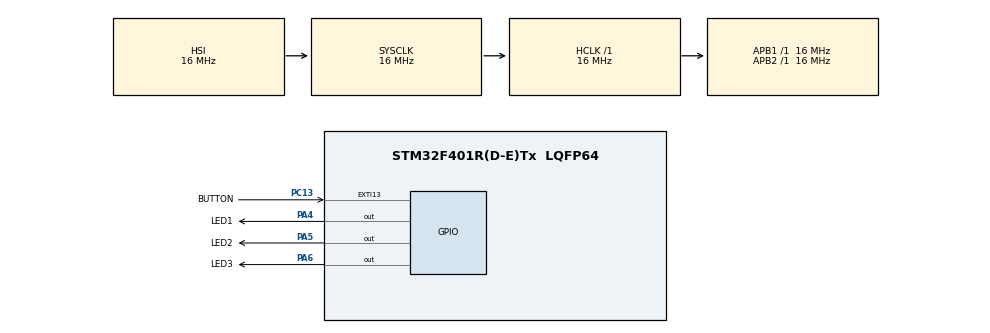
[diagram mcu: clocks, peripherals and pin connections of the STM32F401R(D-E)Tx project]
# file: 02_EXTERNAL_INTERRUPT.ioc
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Mcu.Family=STM32F4
Mcu.Name=STM32F401R(D-E)Tx
Mcu.Package=LQFP64
NVIC.EXTI15_10_IRQn=true\:0\:0\:false\:false\:true\:true\:true\:true
NVIC.PriorityGroup=NVIC_PRIORITYGROUP_4
PA13.Mode=Serial_Wire
PA13.Signal=SYS_JTMS-SWDIO
PA14.Mode=Serial_Wire
PA14.Signal=SYS_JTCK-SWCLK
PA4.GPIO_Label=LED1
PA4.Signal=GPIO_Output
PA5.GPIO_Label=LED2
PA5.Signal=GPIO_Output
PA6.GPIO_Label=LED3
PA6.Signal=GPIO_Output
PC13-ANTI_TAMP.GPIO_Label=BUTTON
PC13-ANTI_TAMP.GPIO_ModeDefaultEXTI=GPIO_MODE_IT_FALLING
PC13-ANTI_TAMP.GPIO_PuPd=GPIO_PULLUP
PC13-ANTI_TAMP.Signal=GPXTI13
ProjectManager.HeapSize=0x200
ProjectManager.StackSize=0x400
ProjectManager.TargetToolchain=STM32CubeIDE
RCC.AHBFreq_Value=16000000
RCC.APB1Freq_Value=16000000
RCC.APB2Freq_Value=16000000
RCC.CortexFreq_Value=16000000
RCC.HSE_VALUE=25000000
RCC.HSI_VALUE=16000000
RCC.LSE_VALUE=32768
RCC.SYSCLKFreq_VALUE=16000000
RCC.VCOOutputFreq_Value=192000000
board=custom

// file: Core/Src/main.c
/* USER CODE BEGIN Header */
/**
  ******************************************************************************
  * @file           : main.c
  * @brief          : Main program body
  ******************************************************************************
  * @attention
  *
  * Copyright (c) 2023 STMicroelectronics.
  * All rights reserved.
  *
  * This software is licensed under terms that can be found in the LICENSE file
  * in the root directory of this software component.
  * If no LICENSE file comes with this software, it is provided AS-IS.
  *
  ******************************************************************************
  */
/* USER CODE END Header */
#include "main.h"

/* USER CODE BEGIN Includes */
#include <stdbool.h>
/* USER CODE END Includes */

/* USER CODE BEGIN PV */
__IO uint8_t contador = 0; //__IO es una variable de tipo volatile
__IO bool flag = false;
/* USER CODE END PV */

void SystemClock_Config(void);
static void MX_GPIO_Init(void);

int main(void)
{

  /* MCU Configuration--------------------------------------------------------*/

  /* Reset of all peripherals, Initializes the Flash interface and the Systick. */
  HAL_Init();

  /* Configure the system clock */
  SystemClock_Config();

  /* Initialize all configured peripherals */
  MX_GPIO_Init();

  /* Infinite loop */
  while (1)
  {
	  if(flag){
		  contador++;
		  flag =  false;
		  if(contador>8){
			  contador = 0;
		  }

	  }

	  if(contador==2){
		  HAL_GPIO_WritePin(LED1_GPIO_Port, LED1_Pin, SET);
	  }else{
		  HAL_GPIO_WritePin(LED1_GPIO_Port, LED1_Pin, RESET);
	  }

	  if(contador==5){
		  HAL_GPIO_WritePin(LED2_GPIO_Port, LED2_Pin, SET);
	  }else{
		  HAL_GPIO_WritePin(LED2_GPIO_Port, LED2_Pin, RESET);
	  }

	  if(contador==7){
		  HAL_GPIO_WritePin(LED3_GPIO_Port, LED3_Pin, SET);
	  }else{
		  HAL_GPIO_WritePin(LED3_GPIO_Port, LED3_Pin, RESET);
	  }

  }
}

void SystemClock_Config(void)
{
  RCC_OscInitTypeDef RCC_OscInitStruct = {0};
  RCC_ClkInitTypeDef RCC_ClkInitStruct = {0};

  /** Configure the main internal regulator output voltage
  */
  __HAL_RCC_PWR_CLK_ENABLE();
  __HAL_PWR_VOLTAGESCALING_CONFIG(PWR_REGULATOR_VOLTAGE_SCALE2);

  /** Initializes the RCC Oscillators according to the specified parameters
  * in the RCC_OscInitTypeDef structure.
  */
  RCC_OscInitStruct.OscillatorType = RCC_OSCILLATORTYPE_HSI;
  RCC_OscInitStruct.HSIState = RCC_HSI_ON;
  RCC_OscInitStruct.HSICalibrationValue = RCC_HSICALIBRATION_DEFAULT;
  RCC_OscInitStruct.PLL.PLLState = RCC_PLL_NONE;
  if (HAL_RCC_OscConfig(&RCC_OscInitStruct) != HAL_OK)
  {
    Error_Handler();
  }

  /** Initializes the CPU, AHB and APB buses clocks
  */
  RCC_ClkInitStruct.ClockType = RCC_CLOCKTYPE_HCLK|RCC_CLOCKTYPE_SYSCLK
                              |RCC_CLOCKTYPE_PCLK1|RCC_CLOCKTYPE_PCLK2;
  RCC_ClkInitStruct.SYSCLKSource = RCC_SYSCLKSOURCE_HSI;
  RCC_ClkInitStruct.AHBCLKDivider = RCC_SYSCLK_DIV1;
  RCC_ClkInitStruct.APB1CLKDivider = RCC_HCLK_DIV1;
  RCC_ClkInitStruct.APB2CLKDivider = RCC_HCLK_DIV1;

  if (HAL_RCC_ClockConfig(&RCC_ClkInitStruct, FLASH_LATENCY_0) != HAL_OK)
  {
    Error_Handler();
  }
}

static void MX_GPIO_Init(void)
{
  GPIO_InitTypeDef GPIO_InitStruct = {0};

  /* GPIO Ports Clock Enable */
  __HAL_RCC_GPIOC_CLK_ENABLE();
  __HAL_RCC_GPIOA_CLK_ENABLE();

  /*Configure GPIO pin Output Level */
  HAL_GPIO_WritePin(GPIOA, LED1_Pin|LED2_Pin|LED3_Pin, GPIO_PIN_RESET);

  /*Configure GPIO pin : BUTTON_Pin */
  GPIO_InitStruct.Pin = BUTTON_Pin;
  GPIO_InitStruct.Mode = GPIO_MODE_IT_FALLING;
  GPIO_InitStruct.Pull = GPIO_PULLUP;
  HAL_GPIO_Init(BUTTON_GPIO_Port, &GPIO_InitStruct);

  /*Configure GPIO pins : LED1_Pin LED2_Pin LED3_Pin */
  GPIO_InitStruct.Pin = LED1_Pin|LED2_Pin|LED3_Pin;
  GPIO_InitStruct.Mode = GPIO_MODE_OUTPUT_PP;
  GPIO_InitStruct.Pull = GPIO_NOPULL;
  GPIO_InitStruct.Speed = GPIO_SPEED_FREQ_LOW;
  HAL_GPIO_Init(GPIOA, &GPIO_InitStruct);

  /* EXTI interrupt init*/
  HAL_NVIC_SetPriority(EXTI15_10_IRQn, 0, 0);
  HAL_NVIC_EnableIRQ(EXTI15_10_IRQn);

}

/* USER CODE BEGIN 4 */

void HAL_GPIO_EXTI_Callback(uint16_t GPIO_Pin){

	switch(GPIO_Pin){
		case BUTTON_Pin:
			flag=true;
	}
}

/* USER CODE END 4 */

void Error_Handler(void)
{
  __disable_irq();
  while (1)
  {
  }
}
